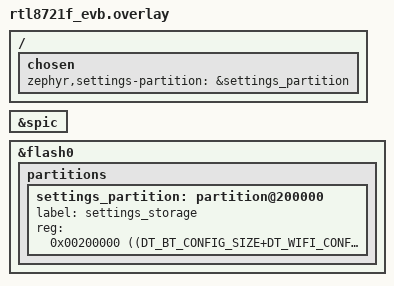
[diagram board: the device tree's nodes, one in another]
/*
 * Copyright (c) 2024 Realtek Semiconductor Corp.
 *
 * SPDX-License-Identifier: Apache-2.0
 */

#define DT_BT_CONFIG_SIZE	DT_SIZE_K(4)
#define DT_WIFI_CONFIG_SIZE	DT_SIZE_K(4)

/ {
	chosen {
		zephyr,settings-partition = &settings_partition;
	};
};

&spic {
	status = "okay";
};

&flash0 {
	partitions {
		settings_partition: partition@200000 {
			label = "settings_storage";
			reg = <0x00200000 ((DT_BT_CONFIG_SIZE+DT_WIFI_CONFIG_SIZE)*2)>;
		};
	};
};
